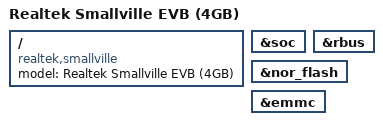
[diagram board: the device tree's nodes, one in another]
// SPDX-License-Identifier: (GPL-2.0-or-later OR BSD-2-Clause)
/*
 * Realtek RTD1920S Smallville EVB
 *
 * Copyright (c) 2024 Realtek Semiconductor Corp.
 */

/dts-v1/;

#include "rtd1920s-smallville.dtsi"

/ {
	compatible = "realtek,smallville", "realtek,rtd1920s";
	model = "Realtek Smallville EVB (4GB)";
};

&soc {
	bootph-all;
};

&rbus {
	bootph-all;
};

&nor_flash {
	bootph-all;
};

&emmc {
	bootph-all;
};
